# M3351 register map
File version: 1.0
Registers are 32-bit, read-write, reset 0x0 unless marked. A register's access mark holds for its fields unless they carry their own. Offsets are from the block's base; [hi:lo] are bit positions; {n}, {i} and the like mark numbered series.

## ELLSI0 — ELLSI Register Map
Base 0x4008A000
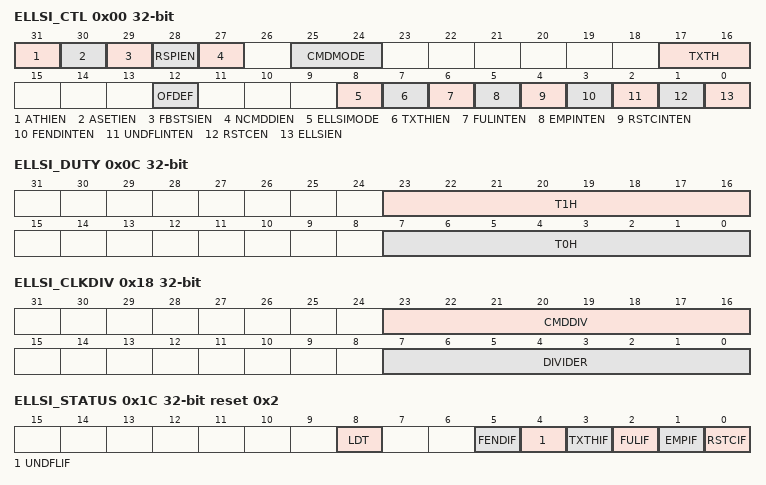
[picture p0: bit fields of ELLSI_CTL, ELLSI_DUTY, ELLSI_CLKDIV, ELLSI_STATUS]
0x00 ELLSI_CTL — ELLSI Control Register
  [31] ATHIEN — AUTO TH20 SET Mode Interrupt Enable Bit
    0=AUTO TH20 SET Mode Interrupt Disabled; 1=AUTO TH20 SET Mode Interrupt Enabled
  [30] ASETIEN — AUTO SET Mode Interrupt Enable Bit
    0=AUTO SET Mode Interrupt Disabled; 1=AUTO SET Mode Interrupt Enabled
  [29] FBSTSIEN — Feedback Status Interrupt Enable Bit
    0=Feedback Status Interrupt Disabled; 1=Feedback Status Interrupt Enabled
  [28] RSPIEN — Normal Command Response Error Interrupt Enable Bit. Note: Normal Command Responses are SET_ID, CHK_ID, and the error flags are ELLSI_CMDSTS[15:8]
    0=Normal Command Response (SET_ID, CHK_ID) Error Interrupt Disabled; 1=Normal Command Response Error Interrupt Enabled
  [27] NCMDDIEN — Normal Command Done Interrupt Enable Bit
    0=Command done interrupt Disabled; 1=Command done interrupt Enabled
  [25:24] CMDMODE — Command Mode
    0=LLSI Mode; 1=Normal Command mode. It includes CLR_ID, SET_ID, CHK_ID, SPE_ID, TH20 SET Mode and Feedback mode; 2=AUTO SET Mode; 3=AUTO TH20 SET Mode
  [17:16] TXTH — Transmit FIFO Threshold. If the valid data count of the transmit FIFO buffer is less than or equal to the TXTH setting, the TXTHIF bit will be set to 1, else the TXTHIF bit will be cleared to 0.
  [12] OFDEF — Output Format Define
    0=Output RGB format; 1=Output GRB format
  [8] ELLSIMODE — ELLSI Mode Select
    0=Software mode; 1=PDMA mode
  [7] TXTHIEN — Transmit FIFO Threshold Interrupt Enable Bit. Note: This bit is only supported in software mode.
    0=TX FIFO threshold interrupt Disabled; 1=TX FIFO threshold interrupt Enabled
  [6] FULINTEN — FIFO Full Interrupt Enable Bit. Note: If this bit is enabled, when the FULIF interrupt flag is set to 1, the ELLSI interrupt signal is generated and inform to CPU.
    0=FIFO full interrupt Disabled; 1=FIFO full interrupt Enabled
  [5] EMPINTEN — FIFO Empty Interrupt Enable Bit. Note: If this bit is enabled, when the EMPIF interrupt flag is set to 1, the ELLSI interrupt signal is generated and inform to CPU.
    0=FIFO empty interrupt Disabled; 1=FIFO empty interrupt Enabled
  [4] RSTCINTEN — Reset Command Interrupt Enable Bit. Note: If this bit is enabled, when the RSTCIF interrupt flag is set to 1, the ELLSI interrupt signal is generated and inform to CPU.
    0=Reset command interrupt Disabled; 1=Reset command interrupt Enabled
  [3] FENDINTEN — Frame End Interrupt Enable Bit. Note: If this bit is enabled, when the FENDIF interrupt flag is set to 1, the ELLSI interrupt signal is generated and inform to CPU.
    0=Frame end interrupt Disabled; 1=Frame end interrupt Enabled
  [2] UNDFLINTEN — Underflow Interrupt Enable Bit. Note: If this bit is enabled, when the UNDFLIF interrupt flag is set to 1, the ELLSI interrupt signal is generated and inform to CPU.
    0=Underflow interrupt Disabled; 1=Underflow interrupt Enabled
  [1] RSTCEN — Reset Command Function Enable Bit. Note: If this bit is enabled, when FIFO and shift register are both empty, ELLSI will send reset command out.
    0=Reset command function Disabled; 1=Reset command function Enabled
  [0] ELLSIEN — ELLSI Enable Bit
    0=ELLSI Disabled; 1=ELLSI Enabled
0x04 ELLSI_RSTPERIOD — ELLSI Reset Period Control Register
  [15:0] RSTPERIOD — Reset Command Period. This field is used to adjust the time of reset command.
0x08 ELLSI_PERIOD — ELLSI Period Control Register
  [7:0] PERIOD — ELLSI Period Register. This field is used to define data transfer time (TH+TL).
0x0C ELLSI_DUTY — ELLSI Duty Control Register
  [23:16] T1H — T1H Data Register. This field is used to define the time of T1H. The time of
  [7:0] T0H — T0H Data Register. This field is used to define the time of T0H. The time of
0x10 ELLSI_DATA wo
  [31:0] DATA — Data Transmit Register. The data transmit registers pass through the transmitted data into the 4-level transmit FIFO buffers.
0x14 ELLSI_PCNT — ELLSI Pixel Count Register
  [11:0] PCNT — Pixel Count Register. User should write a frame size to this register before transfer. For example, if there are a total of 5 LED (5 pixels) in frame, user should write 5 to this control register.
0x18 ELLSI_CLKDIV — ELLSI Clock Divider Register
  [23:16] CMDDIV — ELLSI Command Clock Divider. It indicates the ELLSI command clock
  [7:0] DIVIDER — ELLSI Clock Divider. It indicates the ELLSI clock
0x1C ELLSI_STATUS reset 0x2
  [8] LDT — Last Data Transmit
  [5] FENDIF — Frame End Interrupt Flag. This bit indicates that ELLSI has finished data transmission (FIFO empty shift register empty). When ELLSI transfer finish (FIFO empty shift register empty) this bit is set to 1. User can use this flag to prepare data in advance. Software can write 1 to clear this bit.
  [4] UNDFLIF — Under Flow Interrupt Flag. Each transmission ELLSI reads 3 bytes data from the FIFO. This bit is set to 1 when ELLSI reads the FIFO and the valid data in FIFO is less than 3 bytes. Software can write 1 to clear this bit.
  [3] TXTHIF — Transmit FIFO Threshold Interrupt Flag
    0=The valid data count within the transmit FIFO buffer is larger than the setting value of TXTH; 1=The valid data count within the transmit FIFO buffer is less than or equal to the setting value of TXTH
  [2] FULIF — FIFO Full Interrupt Flag
    0=Transmit FIFO buffer is not full; 1=Transmit FIFO buffer is full
  [1] EMPIF — FIFO Empty Interrupt Flag
    0=Transmit FIFO buffer is not empty; 1=Transmit FIFO buffer is empty
  [0] RSTCIF — Reset Command Interrupt Flag. This bit indicates that ELLSI has finished reset command transmission.
0x20 ELLSI_OCTL — ELLSI Output Control Register
  [0] IDOS — Idle Output Control
    0=Idle will output 0; 1=Idle will output 1
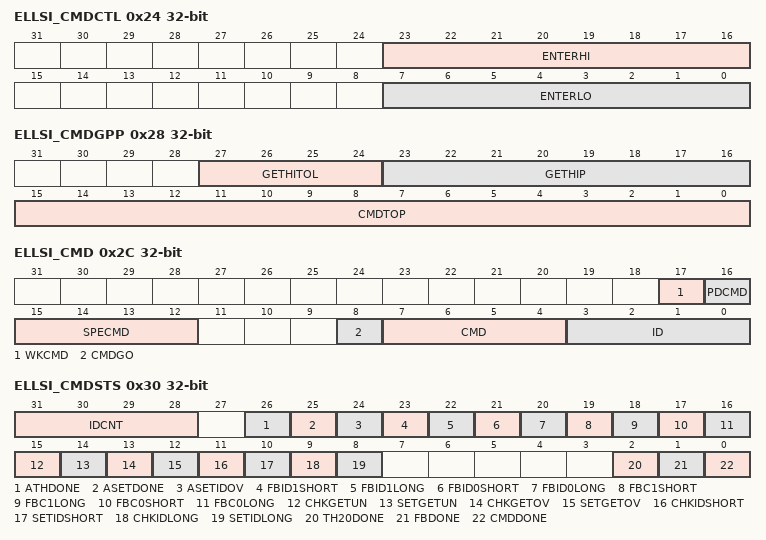
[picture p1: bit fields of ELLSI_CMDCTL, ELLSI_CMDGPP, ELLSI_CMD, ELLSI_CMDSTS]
0x24 ELLSI_CMDCTL — ELLSI Command Control Register
  [23:16] ENTERHI — Enter Command HI Period. Enter Command HI Period (40us).
  [7:0] ENTERLO — Enter Command Low Period. Enter Command Low Period (10us).
0x28 ELLSI_CMDGPP — ELLSI Command Get Pulse Period Register
  [27:24] GETHITOL — Get HI Pulse Tolerance Register. It can set tolerance Get HI Pulse Period.
  [23:16] GETHIP — Get HI Pulse Period Register. Time period threshold to check HI Pulse.
  [15:0] CMDTOP — Command Timeout Period Register. Time period of the command timeout.
0x2C ELLSI_CMD — ELLSI Command Register
  [17] WKCMD — Wakeup Command. When sending data, user can use this bit to send wakeup pulse after data. This bit will be cleard automatically by hardware after receiving low pulse.
  [16] PDCMD — Power-down Command. When sending data, user can use this bit to send 0x5a after data. This bit will be cleard automatically by hardware.
  [15:12] SPECMD — Special Command
    0=Normal command or no command; 1=Feedback count command; 2=Feedback ID command; 3=TH20 SET command; 4=Send Data
  [8] CMDGO — Command Go Bit. When this bit is set, it starts the command. This bit will be cleard automatically by hardware.
  [7:4] CMD — 4-bit Command. 4-bit command.
  [3:0] ID — 4-bit Command ID. 4-bit ID.
0x30 ELLSI_CMDSTS — ELLSI Command Status Register
  [31:28] IDCNT — ID Count Register. Number of Feedback Pulse. It can also be set when the register is written. Note: IDCNT will be updated only when AUTO SET Mode is done.
  [26] ATHDONE — AUTO TH20 SET Mode Done Flag. It will be set to 1 when AUTO TH20 SET Mode is done. Software can write 1 to clear this bit. Note: ATHIEN (ELLSI_CTL[31]) need to be set.
  [25] ASETDONE — AUTO SET Mode Done Flag. It will be set to 1 when AUTO SET Mode is done. Software can write 1 to clear this bit. Note: ASETIEN (ELLSI_CTL[30]) need to be set.
  [24] ASETIDOV — AUTO SET Mode Feedback ID Overflow Flag. It will be set to 1 when setting ID 4b'1111, and get two pulses back. Software can write 1 to clear this bit. Note: ASETIEN (ELLSI_CTL[30]) need to be set.
  [23] FBID1SHORT — Feedback ID 1 Pulse Short Flag. It will be set to 1 when the feedback ID 1 pulse shorter than tolerance. Software can write 1 to clear this bit. Note: FBSTSIEN (ELLSI_CTL[29]) need to be set.
  [22] FBID1LONG — Feedback ID 1 Pulse Long Flag. It will be set to 1 when the feedback ID 1 pulse longer than tolerance. Software can write 1 to clear this bit. Note: FBSTSIEN (ELLSI_CTL[29]) need to be set.
  [21] FBID0SHORT — Feedback ID 0 Pulse Short Flag. It will be set to 1 when the feedback ID 0 pulse shorter than tolerance. Software can write 1 to clear this bit. Note: FBSTSIEN (ELLSI_CTL[29]) need to be set.
  [20] FBID0LONG — Feedback ID 0 Pulse Long Flag. It will be set to 1 when the feedback ID 0 pulse longer than tolerance. Software can write 1 to clear this bit. Note: FBSTSIEN (ELLSI_CTL[29]) need to be set.
  [19] FBC1SHORT — Feedback Count 1 Pulse Short Flag. It will be set to 1 when the feedback count 1 pulse shorter than tolerance. Software can write 1 to clear this bit. Note: FBSTSIEN (ELLSI_CTL[29]) need to be set.
  [18] FBC1LONG — Feedback Count 1 Pulse Long Flag. It will be set to 1 when the feedback count 1 pulse longer than tolerance. Software can write 1 to clear this bit. Note: FBSTSIEN (ELLSI_CTL[29]) need to be set.
  [17] FBC0SHORT — Feedback Count 0 Pulse Short Flag. It will be set to 1 when the feedback count 0 pulse shorter than tolerance. Software can write 1 to clear this bit. Note: FBSTSIEN (ELLSI_CTL[29]) need to be set.
  [16] FBC0LONG — Feedback Count 0 Pulse Long Flag. It will be set to 1 when the feedback count 0 pulse longer than tolerance. Software can write 1 to clear this bit. Note: FBSTSIEN (ELLSI_CTL[29]) need to be set.
  [15] CHKGETUN — Check ID Get Pulse Underflow Flag. It will be set to 1 when ELLSI receive less than one pulse at the Check ID Command Get pulse phase. Software can write 1 to clear this bit. Note: RSPIEN (ELLSI_CTL[28]) need to be set.
  [14] SETGETUN — SET ID Get Pulse Underflow Flag. It will be set to 1 when ELLSI receive less than one pulse at the Set ID Command Get pulse phase. Software can write 1 to clear this bit. Note: RSPIEN (ELLSI_CTL[28]) need to be set.
  [13] CHKGETOV — Check ID Get Pulse Overflow Flag. It will be set to 1 when ELLSI receive more than one pulse at the Check ID Command Get pulse phase. Software can write 1 to clear this bit. Note: RSPIEN (ELLSI_CTL[28]) need to be set.
  [12] SETGETOV — SET ID Get Pulse Overflow Flag. It will be set to 1 when ELLSI receive more than one pulse at the Set ID Command Get pulse phase. Software can write 1 to clear this bit. Note: RSPIEN (ELLSI_CTL[28]) need to be set.
  [11] CHKIDSHORT — Check ID Get Pulse Short Flag. It will be set to 1 when the pulse shorter than tolerance at Check ID Command Get pulse phase. Software can write 1 to clear this bit. Note: RSPIEN (ELLSI_CTL[28]) need to be set.
  [10] SETIDSHORT — Set ID Get Pulse Short Flag. It will be set to 1 when the pulse shorter than tolerance at Set ID Command Get pulse phase. Software can write 1 to clear this bit. Note: RSPIEN (ELLSI_CTL[28]) need to be set.
  [9] CHKIDLONG — Check ID Get Pulse Long Flag. It will be set to 1 when the pulse longer than tolerance at Check ID Command Get pulse phase. Software can write 1 to clear this bit. Note: RSPIEN (ELLSI_CTL[28]) need to be set.
  [8] SETIDLONG — Set ID Get Pulse Long Flag. It will be set to 1 when the pulse longer than tolerance at Set ID Command Get pulse phase. Software can write 1 to clear this bit. Note: RSPIEN (ELLSI_CTL[28]) need to be set.
  [2] TH20DONE — TH20 Command Done Flag. It will be set to 1 when TH20 SET Command done in Normal Command Mode. Software can write 1 to clear this bit. Note: NCMDDIEN (ELLSI_CTL[27]) need to be set.
  [1] FBDONE — Feedback Command Done. It will be set to 1 when Feedback Command done in Normal Command Mode. Software can write 1 to clear this bit. Note: FBSTSIEN (ELLSI_CTL[29]) need to be set.
  [0] CMDDONE — Normal Command Done. It will be set to 1 when Command (SET_ID, CLR_ID, CHK_ID) done in Normal Command Mode. Software can write 1 to clear this bit. Note: NCMDDIEN (ELLSI_CTL[27]) need to be set.
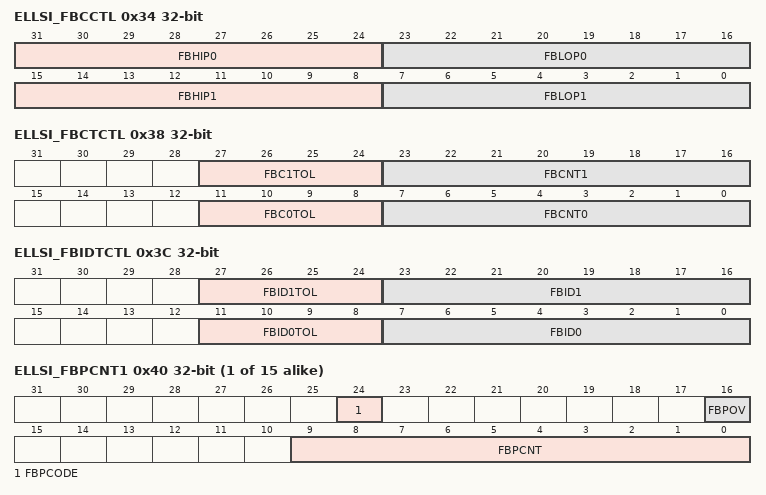
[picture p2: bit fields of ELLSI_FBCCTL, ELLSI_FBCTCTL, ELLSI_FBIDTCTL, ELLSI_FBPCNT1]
0x34 ELLSI_FBCCTL — ELLSI Feedback Command Control Register
  [31:24] FBHIP0 — Feedback Command HI Period 0. Feedback Command High Period 0. 0 _ 0
  [23:16] FBLOP0 — Feedback Command Low Period 0. Feedback Command Low Period 0. 0 _ 0
  [15:8] FBHIP1 — Feedback Command HI Period 1. Feedback Command High Period 1. 1 _ 1
  [7:0] FBLOP1 — Feedback Command Low Period 1. Feedback Command High Period 1. 1 _ 1
0x38 ELLSI_FBCTCTL — ELLSI Feedback Count Timing Control Register
  [27:24] FBC1TOL — Feedback Count 1 Tolerance Register. It can set tolerance Feedback Count 1 Pulse Period. 1 +1 (+1). 1
  [23:16] FBCNT1 — Feedback Count 1 Period Register. Time period threshold to check Feedback Count 1. +1 (+1). 1
  [11:8] FBC0TOL — Feedback Count 0 Tolerance Register. It can set tolerance Feedback Count 0 Pulse Period. 0 +1 (+1). 0
  [7:0] FBCNT0 — Feedback Count 0 Period Register. Time period threshold to check Feedback Count 0. 0 +1 (+1). 0
0x3C ELLSI_FBIDTCTL — ELLSI Feedback ID Timing Control Register
  [27:24] FBID1TOL — Feedback Strip ID 1 Tolerance Register. It can set tolerance Feedback Strip ID data 1 Pulse Period. 1 +1 (+1). 1
  [23:16] FBID1 — Feedback Strip ID 1 Period Register. Time period threshold to check Feedback Strip ID data 1. +1 (+1). 1
  [11:8] FBID0TOL — Feedback Strip ID 0 Tolerance Register. It can set tolerance Feedback Strip ID data 0 Pulse Period. 0 +1 (+1). 0
  [7:0] FBID0 — Feedback Strip ID 0 Period Register. Time period threshold to check Feedback Strip ID data 0. 0 +1 (+1). 0
{0x38+8i} ELLSI_FBPCNT{i} (i=1..15) — ELLSI Feedback Pixel Count Register {i}
  [24] FBPCODE — Feedback Pixel Code. The code feedback from the LED. This value is the same as the last pixel code in the Feedback count command Mode.
  [16] FBPOV — Feedback Pixel Count Overflow Flag. It will be set to 1 when feedback pixel count over 1024. Write 1 to clear this register. Note: FBSTSIEN (ELLSI_CTL[29]) need to be set.
  [9:0] FBPCNT — Feedback Pixel Count. Read this register to get feedback pixel count value.
{0x3C+8i} ELLSI_FBSID{i} (i=1..15) — ELLSI Feedback Strip ID Register {i}
  [31:0] FBSID — Feedback Strip ID. 32-bit Feedback Strip ID.
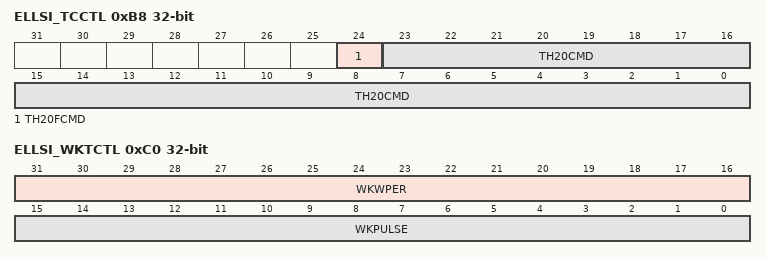
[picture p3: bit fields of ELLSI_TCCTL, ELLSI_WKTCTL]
0xB8 ELLSI_TCCTL — ELLSI TH20 Command Control Register
  [24] TH20FCMD — Force TH20 Command. Set this bit to use TH20CMD register as TH20 24-bit command.
  [23:0] TH20CMD — 24-bit TH20 Command Data. 24-bit TH20 command data.
0xBC ELLSI_TCTCTL — ELLSI TH20 Command Timing Control Register
  [7:0] TH20HI — TH20 Command HI Period. TH20 Command High Period. 20 _ 20
0xC0 ELLSI_WKTCTL — ELLSI Wakeup Command Timing Control Register
  [31:16] WKWPER — Wakeup Wait Period. A period of time include wakeup pulse and low period after sending data.
  [15:0] WKPULSE — Wakeup Pulse Period. Wakeup Pulse Period.

## ELLSI1 — ELLSI Register Map
Base 0x4008B000
Same registers: ELLSI0_NS 0x5008A000, ELLSI1_NS 0x5008B000
Registers as ELLSI0; these are added or differ:
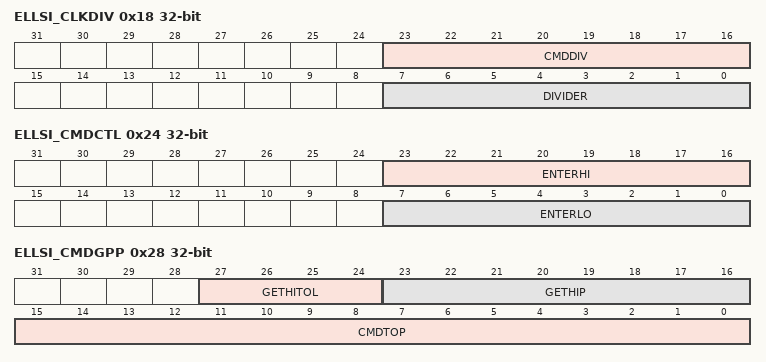
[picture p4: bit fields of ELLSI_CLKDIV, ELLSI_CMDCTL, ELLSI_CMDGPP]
0x18 ELLSI_CLKDIV — ELLSI Clock Divider Register
  [23:16] CMDDIV — ELLSI Command Clock Divider. It indicates the ELLSI command clock, _ +1 (+1)
  [7:0] DIVIDER — ELLSI Clock Divider. It indicates the ELLSI clock, +1
0x24 ELLSI_CMDCTL — ELLSI Command Control Register
  [23:16] ENTERHI — Enter Command HI Period. Enter Command HI Period (40us). _
  [7:0] ENTERLO — Enter Command Low Period. Enter Command Low Period (10us). _
0x28 ELLSI_CMDGPP — ELLSI Command Get Pulse Period Register
  [27:24] GETHITOL — Get HI Pulse Tolerance Register. It can set tolerance Get HI Pulse Period. +1 (+1)
  [23:16] GETHIP — Get HI Pulse Period Register. Time period threshold to check HI Pulse. +1 (+1)
  [15:0] CMDTOP — Command Timeout Period Register. Time period of the command timeout. +1 (+1)
